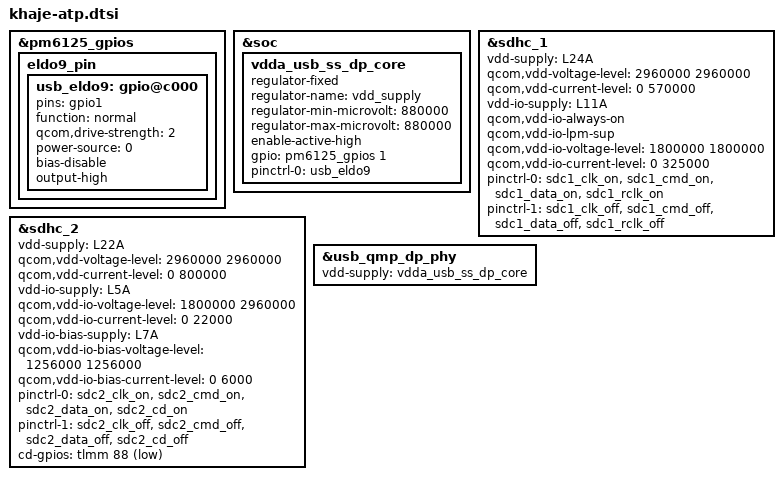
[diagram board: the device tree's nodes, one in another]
#include <dt-bindings/gpio/gpio.h>

&pm6125_gpios {
	eldo9_pin {
		usb_eldo9:gpio@c000 {
			pins = "gpio1";
			function = "normal";
			qcom,drive-strength = <2>;
			power-source = <0>;
			bias-disable;
			output-high;
		};
	};
};

&soc {
	vdda_usb_ss_dp_core: vdda_usb_ss_dp_core {
		compatible = "regulator-fixed";
		regulator-name = "vdd_supply";
		regulator-min-microvolt = <880000>;
		regulator-max-microvolt = <880000>;
		enable-active-high;
		gpio = <&pm6125_gpios 1 GPIO_ACTIVE_HIGH>;
		pinctrl-names = "default";
		pinctrl-0 = <&usb_eldo9>;
	};
};

&sdhc_1 {
	vdd-supply = <&L24A>;
	qcom,vdd-voltage-level = <2960000 2960000>;
	qcom,vdd-current-level = <0 570000>;

	vdd-io-supply = <&L11A>;
	qcom,vdd-io-always-on;
	qcom,vdd-io-lpm-sup;
	qcom,vdd-io-voltage-level = <1800000 1800000>;
	qcom,vdd-io-current-level = <0 325000>;

	pinctrl-names = "active", "sleep";
	pinctrl-0 = <&sdc1_clk_on &sdc1_cmd_on &sdc1_data_on
					&sdc1_rclk_on>;
	pinctrl-1 = <&sdc1_clk_off &sdc1_cmd_off &sdc1_data_off
					&sdc1_rclk_off>;

	status = "ok";
};

&sdhc_2 {
	vdd-supply = <&L22A>;
	qcom,vdd-voltage-level = <2960000 2960000>;
	qcom,vdd-current-level = <0 800000>;

	vdd-io-supply = <&L5A>;
	qcom,vdd-io-voltage-level = <1800000 2960000>;
	qcom,vdd-io-current-level = <0 22000>;

	vdd-io-bias-supply = <&L7A>;
	qcom,vdd-io-bias-voltage-level = <1256000 1256000>;
	qcom,vdd-io-bias-current-level = <0 6000>;

	pinctrl-names = "active", "sleep";
	pinctrl-0 = <&sdc2_clk_on  &sdc2_cmd_on &sdc2_data_on &sdc2_cd_on>;
	pinctrl-1 = <&sdc2_clk_off &sdc2_cmd_off &sdc2_data_off &sdc2_cd_off>;

	cd-gpios = <&tlmm 88 GPIO_ACTIVE_LOW>;

	status = "ok";
};

&usb_qmp_dp_phy {
	vdd-supply = <&vdda_usb_ss_dp_core>;
};
